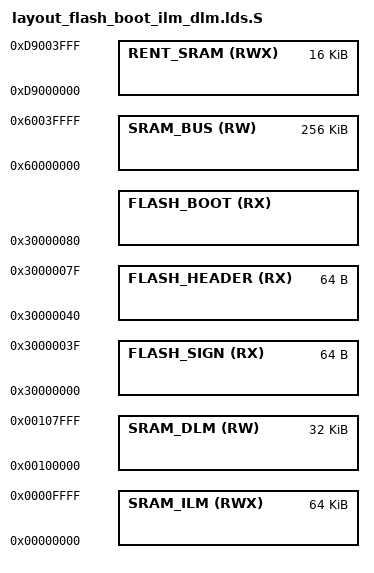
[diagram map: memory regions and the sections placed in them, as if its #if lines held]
MEMORY
{
    SRAM_ILM    (RWX)     : ORIGIN = 0x00000000, LENGTH = 64K
    SRAM_DLM    (RW)      : ORIGIN = 0x00100000, LENGTH = 32K
    SRAM_BUS    (RW)      : ORIGIN = 0x60000000, LENGTH = 256K
    RENT_SRAM   (RWX)     : ORIGIN = 0xD9000000, LENGTH = 16K
#if (SECURE_BOOT == 1)
    FLASH_SIGN(RX)        : ORIGIN = 0x30000000, LENGTH = 64
#else
    FLASH_SIGN(RX)        : ORIGIN = 0x30000000, LENGTH = 0
#endif
    FLASH_HEADER(RX)      : ORIGIN = 0x30000000+LENGTH(FLASH_SIGN), LENGTH = 64
    FLASH_BOOT  (RX)      : ORIGIN = 0x30000000+LENGTH(FLASH_SIGN)+LENGTH(FLASH_HEADER), LENGTH = (BL_SIZE)-LENGTH(FLASH_SIGN)-LENGTH(FLASH_HEADER)

    /* ota_data(4K), sa_table(4K), mac_table(4K), pad_table(4K), ROM_BOOT(4K)*/
    FLASH_PARAM (RX)      : ORIGIN = (0x30000000+(BL_SIZE)), LENGTH = (4K+4K+4K+4K+4K+SETTING_PARTITION_USER_RAW_SIZE)
    FLASH_XIP1       (RX) : ORIGIN = (0x30000000+(BL_SIZE))+LENGTH(FLASH_PARAM), LENGTH = (SETTING_PARTITION_MAIN_SIZE)
    FLASH_XIP2       (RX) : ORIGIN = (0x30000000+(BL_SIZE))+LENGTH(FLASH_PARAM)+LENGTH(FLASH_XIP1), LENGTH = (SETTING_PARTITION_MAIN_SIZE)
}

REGION_ALIAS("REGION_TEXT_FAST" , SRAM_ILM);
REGION_ALIAS("REGION_BOOT"      , FLASH_BOOT);
REGION_ALIAS("REGION_PARAM"     , FLASH_PARAM);
REGION_ALIAS("REGION_MAIN1"     , FLASH_XIP1);
REGION_ALIAS("REGION_MAIN2"     , FLASH_XIP2);
#if (FOTA_OPTION == 2)
REGION_ALIAS("REGION_LAST"      , FLASH_XIP2);
#else
REGION_ALIAS("REGION_LAST"      , FLASH_XIP1);
#endif
REGION_ALIAS("REGION_DATA"      , SRAM_DLM);
REGION_ALIAS("REGION_DATA_FAST" , SRAM_DLM);
REGION_ALIAS("REGION_BSS"       , SRAM_DLM);
REGION_ALIAS("REGION_LPRAM"     , RENT_SRAM);
